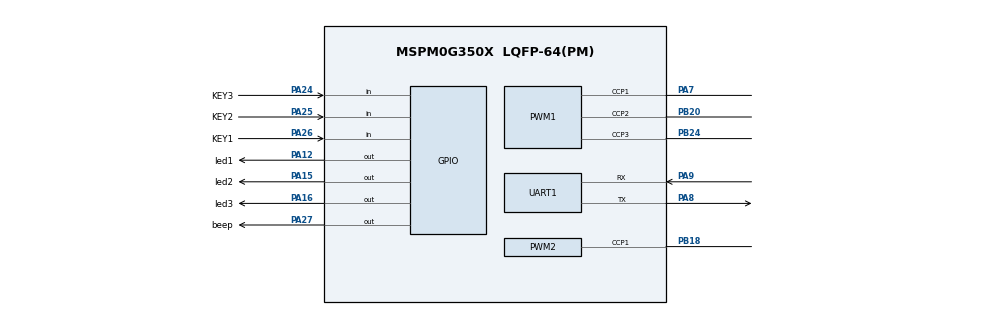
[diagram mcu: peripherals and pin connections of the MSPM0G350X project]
/**
 * @cliArgs --device "MSPM0G350X" --part "Default" --package "LQFP-64(PM)" --product "mspm0_sdk@2.04.00.06"
 * @versions {"tool":"1.23.1+4034"}
 */

/**
 * Import the modules used in this configuration.
 */
const GPIO    = scripting.addModule("/ti/driverlib/GPIO", {}, false);
const GPIO1   = GPIO.addInstance();
const GPIO2   = GPIO.addInstance();
const GPIO3   = GPIO.addInstance();
const GPIO4   = GPIO.addInstance();
const GPIO5   = GPIO.addInstance();
const PWM     = scripting.addModule("/ti/driverlib/PWM", {}, false);
const PWM1    = PWM.addInstance();
const PWM2    = PWM.addInstance();
const SYSCTL  = scripting.addModule("/ti/driverlib/SYSCTL");
const SYSTICK = scripting.addModule("/ti/driverlib/SYSTICK");
const TIMER   = scripting.addModule("/ti/driverlib/TIMER", {}, false);
const TIMER1  = TIMER.addInstance();
const TIMER2  = TIMER.addInstance();
const UART    = scripting.addModule("/ti/driverlib/UART", {}, false);
const UART1   = UART.addInstance();
const UART2   = UART.addInstance();

/**
 * Write custom configuration values to the imported modules.
 */
const gate7  = system.clockTree["MFCLKGATE"];
gate7.enable = true;

GPIO1.$name                              = "KEY";
GPIO1.port                               = "PORTA";
GPIO1.associatedPins.create(6);
GPIO1.associatedPins[0].direction        = "INPUT";
GPIO1.associatedPins[0].internalResistor = "PULL_DOWN";
GPIO1.associatedPins[0].polarity         = "RISE";
GPIO1.associatedPins[0].$name            = "KEY1";
GPIO1.associatedPins[0].assignedPin      = "26";
GPIO1.associatedPins[0].pin.$assign      = "PA26";
GPIO1.associatedPins[1].direction        = "INPUT";
GPIO1.associatedPins[1].$name            = "KEY2";
GPIO1.associatedPins[1].polarity         = "RISE";
GPIO1.associatedPins[1].internalResistor = "PULL_DOWN";
GPIO1.associatedPins[1].pin.$assign      = "PA25";
GPIO1.associatedPins[2].$name            = "KEY3";
GPIO1.associatedPins[2].direction        = "INPUT";
GPIO1.associatedPins[2].polarity         = "RISE";
GPIO1.associatedPins[2].internalResistor = "PULL_DOWN";
GPIO1.associatedPins[2].pin.$assign      = "PA24";
GPIO1.associatedPins[3].$name            = "KEY4";
GPIO1.associatedPins[3].assignedPin      = "23";
GPIO1.associatedPins[3].direction        = "INPUT";
GPIO1.associatedPins[3].polarity         = "RISE";
GPIO1.associatedPins[3].internalResistor = "PULL_DOWN";
GPIO1.associatedPins[4].$name            = "KEY5";
GPIO1.associatedPins[4].assignedPin      = "22";
GPIO1.associatedPins[4].direction        = "INPUT";
GPIO1.associatedPins[4].polarity         = "RISE";
GPIO1.associatedPins[4].internalResistor = "PULL_DOWN";
GPIO1.associatedPins[5].$name            = "KEY6";
GPIO1.associatedPins[5].assignedPin      = "21";
GPIO1.associatedPins[5].direction        = "INPUT";
GPIO1.associatedPins[5].polarity         = "RISE";
GPIO1.associatedPins[5].internalResistor = "PULL_DOWN";

const Board = scripting.addModule("/ti/driverlib/Board", {}, false);

GPIO2.port                          = "PORTA";
GPIO2.$name                         = "buzzer";
GPIO2.associatedPins[0].$name       = "beep";
GPIO2.associatedPins[0].pin.$assign = "PA27";

GPIO3.$name                         = "lazer";
GPIO3.port                          = "PORTB";
GPIO3.associatedPins.create(2);
GPIO3.associatedPins[0].assignedPin = "9";
GPIO3.associatedPins[0].$name       = "lazer1";
GPIO3.associatedPins[1].$name       = "lazer2";
GPIO3.associatedPins[1].assignedPin = "8";

GPIO4.$name                          = "OLED";
GPIO4.port                           = "PORTA";
GPIO4.associatedPins.create(2);
GPIO4.associatedPins[0].$name        = "SCL";
GPIO4.associatedPins[0].initialValue = "SET";
GPIO4.associatedPins[0].ioStructure  = "OD";
GPIO4.associatedPins[0].assignedPin  = "0";
GPIO4.associatedPins[1].$name        = "SDA";
GPIO4.associatedPins[1].initialValue = "SET";
GPIO4.associatedPins[1].ioStructure  = "OD";
GPIO4.associatedPins[1].assignedPin  = "1";

GPIO5.$name                         = "led";
GPIO5.port                          = "PORTA";
GPIO5.associatedPins.create(3);
GPIO5.associatedPins[0].$name       = "led1";
GPIO5.associatedPins[0].pin.$assign = "PA12";
GPIO5.associatedPins[1].$name       = "led2";
GPIO5.associatedPins[1].pin.$assign = "PA15";
GPIO5.associatedPins[2].$name       = "led3";
GPIO5.associatedPins[2].pin.$assign = "PA16";

PWM1.clockDivider                            = 8;
PWM1.timerStartTimer                         = true;
PWM1.timerCount                              = 400;
PWM1.clockPrescale                           = 200;
PWM1.ccIndex                                 = [1,2,3];
PWM1.ccIndexCmpl                             = [1,2,3];
PWM1.$name                                   = "PWM";
PWM1.ccp1PinConfig.direction                 = scripting.forceWrite("OUTPUT");
PWM1.ccp1PinConfig.hideOutputInversion       = scripting.forceWrite(false);
PWM1.ccp1PinConfig.onlyInternalResistor      = scripting.forceWrite(false);
PWM1.ccp1PinConfig.passedPeripheralType      = scripting.forceWrite("Digital");
PWM1.ccp1PinConfig.$name                     = "ti_driverlib_gpio_GPIOPinGeneric4";
PWM1.PWM_CHANNEL_2.$name                     = "ti_driverlib_pwm_PWMTimerCC5";
PWM1.PWM_CHANNEL_2.invert                    = true;
PWM1.PWM_CHANNEL_3.$name                     = "ti_driverlib_pwm_PWMTimerCC2";
PWM1.PWM_CHANNEL_3.invert                    = true;
PWM1.ccp2PinConfig.direction                 = scripting.forceWrite("OUTPUT");
PWM1.ccp2PinConfig.hideOutputInversion       = scripting.forceWrite(false);
PWM1.ccp2PinConfig.onlyInternalResistor      = scripting.forceWrite(false);
PWM1.ccp2PinConfig.passedPeripheralType      = scripting.forceWrite("Digital");
PWM1.ccp2PinConfig.$name                     = "ti_driverlib_gpio_GPIOPinGeneric9";
PWM1.ccp3PinConfig.direction                 = scripting.forceWrite("OUTPUT");
PWM1.ccp3PinConfig.hideOutputInversion       = scripting.forceWrite(false);
PWM1.ccp3PinConfig.onlyInternalResistor      = scripting.forceWrite(false);
PWM1.ccp3PinConfig.passedPeripheralType      = scripting.forceWrite("Digital");
PWM1.ccp3PinConfig.$name                     = "ti_driverlib_gpio_GPIOPinGeneric6";
PWM1.PWM_CHANNEL_1.$name                     = "ti_driverlib_pwm_PWMTimerCC0";
PWM1.PWM_CHANNEL_1.invert                    = true;
PWM1.peripheral.$assignAllowConflicts        = "TIMA0";
PWM1.peripheral.ccp1Pin.$assign              = "PA7";
PWM1.peripheral.ccp2Pin.$assign              = "PB20";
PWM1.peripheral.ccp3Pin.$assign              = "PB24";
PWM1.ccp1Pin_cmplConfig.direction            = scripting.forceWrite("OUTPUT");
PWM1.ccp1Pin_cmplConfig.hideOutputInversion  = scripting.forceWrite(false);
PWM1.ccp1Pin_cmplConfig.onlyInternalResistor = scripting.forceWrite(false);
PWM1.ccp1Pin_cmplConfig.passedPeripheralType = scripting.forceWrite("Digital");
PWM1.ccp1Pin_cmplConfig.$name                = "ti_driverlib_gpio_GPIOPinGeneric5";
PWM1.ccp2Pin_cmplConfig.$name                = "ti_driverlib_gpio_GPIOPinGeneric10";
PWM1.ccp2Pin_cmplConfig.direction            = scripting.forceWrite("OUTPUT");
PWM1.ccp2Pin_cmplConfig.hideOutputInversion  = scripting.forceWrite(false);
PWM1.ccp2Pin_cmplConfig.onlyInternalResistor = scripting.forceWrite(false);
PWM1.ccp2Pin_cmplConfig.passedPeripheralType = scripting.forceWrite("Digital");
PWM1.ccp3Pin_cmplConfig.$name                = "ti_driverlib_gpio_GPIOPinGeneric11";
PWM1.ccp3Pin_cmplConfig.direction            = scripting.forceWrite("OUTPUT");
PWM1.ccp3Pin_cmplConfig.hideOutputInversion  = scripting.forceWrite(false);
PWM1.ccp3Pin_cmplConfig.onlyInternalResistor = scripting.forceWrite(false);
PWM1.ccp3Pin_cmplConfig.passedPeripheralType = scripting.forceWrite("Digital");

PWM2.$name                              = "servo1";
PWM2.ccIndex                            = [1];
PWM2.ccIndexCmpl                        = [1];
PWM2.clockDivider                       = 8;
PWM2.clockPrescale                      = 200;
PWM2.timerCount                         = 400;
PWM2.timerStartTimer                    = true;
PWM2.ccp1PinConfig.direction            = scripting.forceWrite("OUTPUT");
PWM2.ccp1PinConfig.hideOutputInversion  = scripting.forceWrite(false);
PWM2.ccp1PinConfig.onlyInternalResistor = scripting.forceWrite(false);
PWM2.ccp1PinConfig.passedPeripheralType = scripting.forceWrite("Digital");
PWM2.ccp1PinConfig.$name                = "ti_driverlib_gpio_GPIOPinGeneric7";
PWM2.PWM_CHANNEL_1.$name                = "ti_driverlib_pwm_PWMTimerCC1";
PWM2.PWM_CHANNEL_1.invert               = true;
PWM2.peripheral.$assign                 = "TIMA1";
PWM2.peripheral.ccp1Pin.$assign         = "PB18";
PWM2.ccp1Pin_cmplConfig.$name           = "ti_driverlib_gpio_GPIOPinGeneric8";

SYSCTL.forceDefaultClkConfig = true;
SYSCTL.clockTreeEn           = true;

SYSTICK.periodEnable      = true;
SYSTICK.interruptPriority = "0";
SYSTICK.systickEnable     = true;
SYSTICK.period            = 32;

TIMER1.$name              = "TIMER_0";
TIMER1.timerClkDiv        = 8;
TIMER1.timerPeriod        = "10 ms";
TIMER1.timerStartTimer    = true;
TIMER1.interrupts         = ["ZERO"];
TIMER1.timerClkPrescale   = 100;
TIMER1.timerMode          = "PERIODIC_UP";
TIMER1.peripheral.$assign = "TIMG0";

TIMER2.$name            = "TIMER_1";
TIMER2.timerClkDiv      = 8;
TIMER2.timerClkPrescale = 100;
TIMER2.timerStartTimer  = true;
TIMER2.interrupts       = ["ZERO"];
TIMER2.timerPeriod      = "20ms";
TIMER2.timerMode        = "PERIODIC";

UART1.$name                            = "UART_1";
UART1.uartClkSrc                       = "MFCLK";
UART1.enabledInterrupts                = ["RX"];
UART1.peripheral.rxPin.$assign         = "PA9";
UART1.peripheral.txPin.$assign         = "PA8";
UART1.txPinConfig.direction            = scripting.forceWrite("OUTPUT");
UART1.txPinConfig.hideOutputInversion  = scripting.forceWrite(false);
UART1.txPinConfig.onlyInternalResistor = scripting.forceWrite(false);
UART1.txPinConfig.passedPeripheralType = scripting.forceWrite("Digital");
UART1.txPinConfig.$name                = "ti_driverlib_gpio_GPIOPinGeneric2";
UART1.txPinConfig.internalResistor     = "PULL_UP";
UART1.txPinConfig.hiZ                  = "ENABLE";
UART1.txPinConfig.invert               = "ENABLE";
UART1.rxPinConfig.hideOutputInversion  = scripting.forceWrite(false);
UART1.rxPinConfig.onlyInternalResistor = scripting.forceWrite(false);
UART1.rxPinConfig.passedPeripheralType = scripting.forceWrite("Digital");
UART1.rxPinConfig.$name                = "ti_driverlib_gpio_GPIOPinGeneric3";
UART1.rxPinConfig.invert               = "ENABLE";

UART2.$name                            = "UART_3";
UART2.uartClkSrc                       = "MFCLK";
UART2.enabledInterrupts                = ["RX"];
UART2.peripheral.$assign               = "UART3";
UART2.txPinConfig.direction            = scripting.forceWrite("OUTPUT");
UART2.txPinConfig.hideOutputInversion  = scripting.forceWrite(false);
UART2.txPinConfig.onlyInternalResistor = scripting.forceWrite(false);
UART2.txPinConfig.passedPeripheralType = scripting.forceWrite("Digital");
UART2.txPinConfig.$name                = "ti_driverlib_gpio_GPIOPinGeneric12";
UART2.rxPinConfig.hideOutputInversion  = scripting.forceWrite(false);
UART2.rxPinConfig.onlyInternalResistor = scripting.forceWrite(false);
UART2.rxPinConfig.passedPeripheralType = scripting.forceWrite("Digital");
UART2.rxPinConfig.$name                = "ti_driverlib_gpio_GPIOPinGeneric13";

/**
 * Pinmux solution for unlocked pins/peripherals. This ensures that minor changes to the automatic solver in a future
 * version of the tool will not impact the pinmux you originally saw.  These lines can be completely deleted in order to
 * re-solve from scratch.
 */
GPIO1.associatedPins[3].pin.$suggestSolution  = "PA23";
GPIO1.associatedPins[4].pin.$suggestSolution  = "PA22";
GPIO1.associatedPins[5].pin.$suggestSolution  = "PA21";
Board.peripheral.$suggestSolution             = "DEBUGSS";
Board.peripheral.swclkPin.$suggestSolution    = "PA20";
Board.peripheral.swdioPin.$suggestSolution    = "PA19";
GPIO3.associatedPins[0].pin.$suggestSolution  = "PB9";
GPIO3.associatedPins[1].pin.$suggestSolution  = "PB8";
GPIO4.associatedPins[0].pin.$suggestSolution  = "PA0";
GPIO4.associatedPins[1].pin.$suggestSolution  = "PA1";
PWM1.peripheral.ccp1Pin_cmpl.$suggestSolution = "PA4";
PWM1.peripheral.ccp2Pin_cmpl.$suggestSolution = "PA11";
PWM1.peripheral.ccp3Pin_cmpl.$suggestSolution = "PA18";
PWM2.peripheral.ccp1Pin_cmpl.$suggestSolution = "PB5";
TIMER2.peripheral.$suggestSolution            = "TIMG6";
UART1.peripheral.$suggestSolution             = "UART1";
UART2.peripheral.rxPin.$suggestSolution       = "PA13";
UART2.peripheral.txPin.$suggestSolution       = "PA14";
